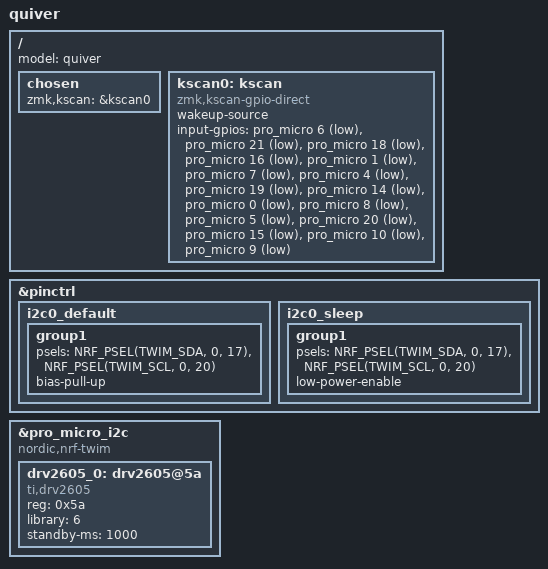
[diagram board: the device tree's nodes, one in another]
/ {
    model = "quiver";

    chosen {
        zmk,kscan = &kscan0;
    };

    kscan0: kscan {
        compatible = "zmk,kscan-gpio-direct";
        wakeup-source;

        input-gpios =
            <&pro_micro   6 (GPIO_ACTIVE_LOW | GPIO_PULL_UP)>,
            <&pro_micro  21 (GPIO_ACTIVE_LOW | GPIO_PULL_UP)>,
            <&pro_micro  18 (GPIO_ACTIVE_LOW | GPIO_PULL_UP)>,
            <&pro_micro  16 (GPIO_ACTIVE_LOW | GPIO_PULL_UP)>,
            <&pro_micro   1 (GPIO_ACTIVE_LOW | GPIO_PULL_UP)>,
            <&pro_micro   7 (GPIO_ACTIVE_LOW | GPIO_PULL_UP)>,
            <&pro_micro   4 (GPIO_ACTIVE_LOW | GPIO_PULL_UP)>,
            <&pro_micro  19 (GPIO_ACTIVE_LOW | GPIO_PULL_UP)>,
            <&pro_micro  14 (GPIO_ACTIVE_LOW | GPIO_PULL_UP)>,
            <&pro_micro   0 (GPIO_ACTIVE_LOW | GPIO_PULL_UP)>,
            <&pro_micro   8 (GPIO_ACTIVE_LOW | GPIO_PULL_UP)>,
            <&pro_micro   5 (GPIO_ACTIVE_LOW | GPIO_PULL_UP)>,
            <&pro_micro  20 (GPIO_ACTIVE_LOW | GPIO_PULL_UP)>,
            <&pro_micro  15 (GPIO_ACTIVE_LOW | GPIO_PULL_UP)>,
            <&pro_micro  10 (GPIO_ACTIVE_LOW | GPIO_PULL_UP)>,
            <&pro_micro   9 (GPIO_ACTIVE_LOW | GPIO_PULL_UP)>;

    };
};

&pinctrl {
    i2c0_default: i2c0_default {
        group1 {
            psels = <NRF_PSEL(TWIM_SDA, 0, 17)>,
                    <NRF_PSEL(TWIM_SCL, 0, 20)>;
            bias-pull-up;
        };
    };

    i2c0_sleep: i2c0_sleep {
        group1 {
            psels = <NRF_PSEL(TWIM_SDA, 0, 17)>,
                    <NRF_PSEL(TWIM_SCL, 0, 20)>;
            low-power-enable;
        };
    };
};

&pro_micro_i2c {
    status = "okay";
    compatible = "nordic,nrf-twim";

    drv2605_0: drv2605@5a {
        compatible = "ti,drv2605";
        reg = <0x5a>;
        library = <6>;  // LRA
        standby-ms = <1000>;
    };
};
